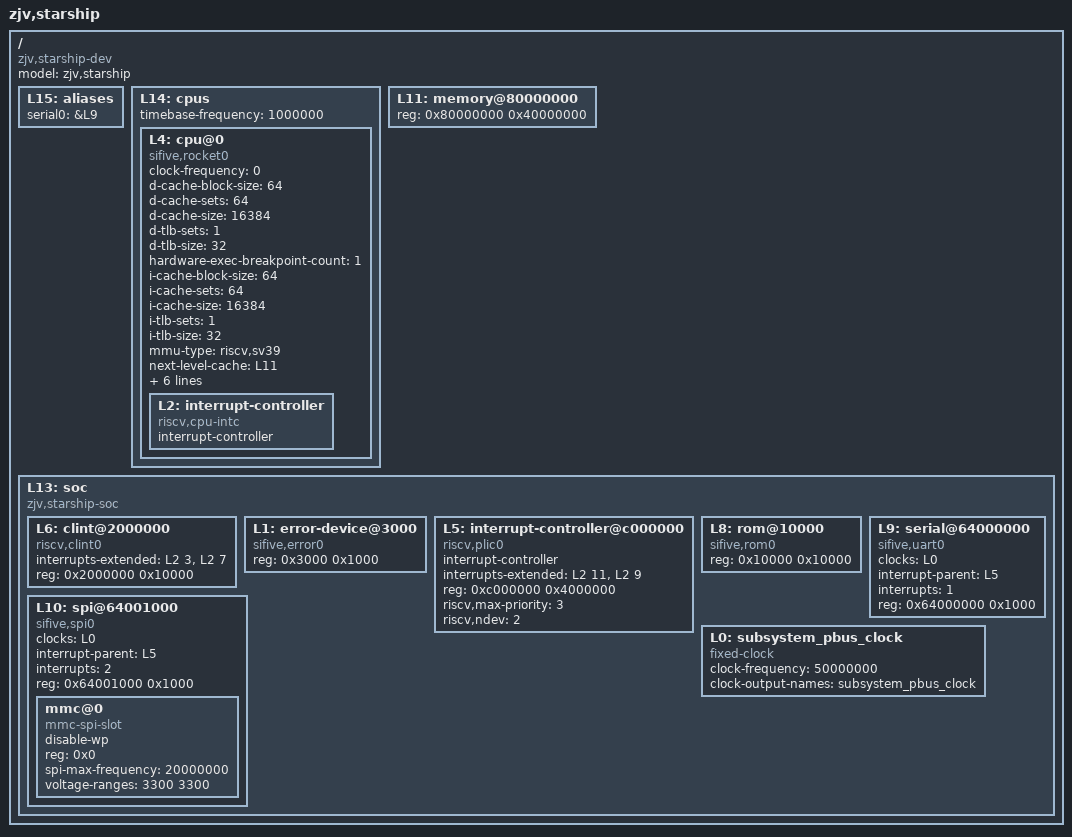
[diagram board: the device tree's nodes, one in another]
/dts-v1/;

/ {
	#address-cells = <1>;
	#size-cells = <1>;
	compatible = "zjv,starship-dev";
	model = "zjv,starship";
	L15: aliases {
		serial0 = &L9;
	};
	L14: cpus {
		#address-cells = <1>;
		#size-cells = <0>;
		timebase-frequency = <1000000>;
		L4: cpu@0 {
			clock-frequency = <0>;
			compatible = "sifive,rocket0", "riscv";
			d-cache-block-size = <64>;
			d-cache-sets = <64>;
			d-cache-size = <16384>;
			d-tlb-sets = <1>;
			d-tlb-size = <32>;
			device_type = "cpu";
			hardware-exec-breakpoint-count = <1>;
			i-cache-block-size = <64>;
			i-cache-sets = <64>;
			i-cache-size = <16384>;
			i-tlb-sets = <1>;
			i-tlb-size = <32>;
			mmu-type = "riscv,sv39";
			next-level-cache = <&L11>;
			reg = <0x0>;
			riscv,isa = "rv64imafdc";
			riscv,pmpgranularity = <4>;
			riscv,pmpregions = <8>;
			status = "okay";
			timebase-frequency = <1000000>;
			tlb-split;
			L2: interrupt-controller {
				#interrupt-cells = <1>;
				compatible = "riscv,cpu-intc";
				interrupt-controller;
			};
		};
	};
	L11: memory@80000000 {
		device_type = "memory";
		reg = <0x80000000 0x40000000>;
	};
	L13: soc {
		#address-cells = <1>;
		#size-cells = <1>;
		compatible = "zjv,starship-soc", "simple-bus";
		ranges;
		L6: clint@2000000 {
			compatible = "riscv,clint0";
			interrupts-extended = <&L2 3 &L2 7>;
			reg = <0x2000000 0x10000>;
			reg-names = "control";
		};
		L1: error-device@3000 {
			compatible = "sifive,error0";
			reg = <0x3000 0x1000>;
		};
		L5: interrupt-controller@c000000 {
			#interrupt-cells = <1>;
			compatible = "riscv,plic0";
			interrupt-controller;
			interrupts-extended = <&L2 11 &L2 9>;
			reg = <0xc000000 0x4000000>;
			reg-names = "control";
			riscv,max-priority = <3>;
			riscv,ndev = <2>;
		};
		L8: rom@10000 {
			compatible = "sifive,rom0";
			reg = <0x10000 0x10000>;
			reg-names = "mem";
		};
		L9: serial@64000000 {
			clocks = <&L0>;
			compatible = "sifive,uart0";
			interrupt-parent = <&L5>;
			interrupts = <1>;
			reg = <0x64000000 0x1000>;
			reg-names = "control";
		};
		L10: spi@64001000 {
			#address-cells = <1>;
			#size-cells = <0>;
			clocks = <&L0>;
			compatible = "sifive,spi0";
			interrupt-parent = <&L5>;
			interrupts = <2>;
			reg = <0x64001000 0x1000>;
			reg-names = "control";
			mmc@0 {
				compatible = "mmc-spi-slot";
				disable-wp;
				reg = <0x0>;
				spi-max-frequency = <20000000>;
				voltage-ranges = <3300 3300>;
			};
		};
		L0: subsystem_pbus_clock {
			#clock-cells = <0>;
			clock-frequency = <50000000>;
			clock-output-names = "subsystem_pbus_clock";
			compatible = "fixed-clock";
		};
	};
};
